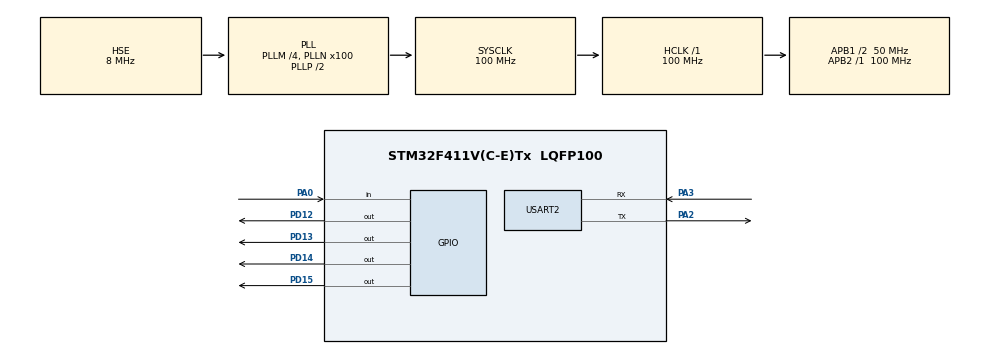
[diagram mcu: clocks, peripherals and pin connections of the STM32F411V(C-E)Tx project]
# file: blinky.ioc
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FREERTOS.Tasks01=defaultTask,24,128,StartDefaultTask,Default,NULL
Mcu.Family=STM32F4
Mcu.Name=STM32F411V(C-E)Tx
Mcu.Package=LQFP100
NVIC.PriorityGroup=NVIC_PRIORITYGROUP_4
NVIC.TIM1_UP_TIM10_IRQn=true\:0\:0\:false\:false\:true\:false\:false\:true
NVIC.TimeBase=TIM1_UP_TIM10_IRQn
NVIC.TimeBaseIP=TIM1
PA0-WKUP.Signal=GPIO_Input
PA13.Mode=Serial_Wire
PA13.Signal=SYS_JTMS-SWDIO
PA14.Mode=Serial_Wire
PA14.Signal=SYS_JTCK-SWCLK
PA2.Mode=Asynchronous
PA2.Signal=USART2_TX
PA3.Mode=Asynchronous
PA3.Signal=USART2_RX
PD12.Signal=GPIO_Output
PD13.Signal=GPIO_Output
PD14.Signal=GPIO_Output
PD15.Signal=GPIO_Output
PH0\ -\ OSC_IN.Mode=HSE-External-Oscillator
PH0\ -\ OSC_IN.Signal=RCC_OSC_IN
PH1\ -\ OSC_OUT.Mode=HSE-External-Oscillator
PH1\ -\ OSC_OUT.Signal=RCC_OSC_OUT
ProjectManager.HeapSize=0x200
ProjectManager.StackSize=0x400
ProjectManager.TargetToolchain=STM32CubeIDE
RCC.48MHZClocksFreq_Value=50000000
RCC.AHBFreq_Value=100000000
RCC.APB1CLKDivider=RCC_HCLK_DIV2
RCC.APB1Freq_Value=50000000
RCC.APB1TimFreq_Value=100000000
RCC.APB2Freq_Value=100000000
RCC.APB2TimFreq_Value=100000000
RCC.CortexFreq_Value=100000000
RCC.HCLKFreq_Value=100000000
RCC.HSE_VALUE=8000000
RCC.HSI_VALUE=16000000
RCC.PLLM=4
RCC.PLLN=100
RCC.PLLSourceVirtual=RCC_PLLSOURCE_HSE
RCC.SYSCLKFreq_VALUE=100000000
RCC.SYSCLKSource=RCC_SYSCLKSOURCE_PLLCLK
RCC.VCOOutputFreq_Value=200000000
USART2.VirtualMode=VM_ASYNC
VP_FREERTOS_VS_CMSIS_V2.Mode=CMSIS_V2
VP_SYS_VS_tim1.Mode=TIM1
board=custom

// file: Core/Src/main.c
/* USER CODE BEGIN Header */
/**
  ******************************************************************************
  * @file           : main.c
  * @brief          : Main program body
  ******************************************************************************
  * @attention
  *
  * <h2><center>&copy; Copyright (c) 2019 STMicroelectronics.
  * All rights reserved.</center></h2>
  *
  * This software component is licensed by ST under BSD 3-Clause license,
  * the "License"; You may not use this file except in compliance with the
  * License. You may obtain a copy of the License at:
  *                        opensource.org/licenses/BSD-3-Clause
  *

  https://www.keil.com/pack/doc/cmsis/RTOS2/html/group__CMSIS__RTOS__PoolMgmt.html#details

  Los grupos de memoria son bloques de memoria de tamaño fijo que son seguros para
  subprocesos. Funcionan mucho más rápido que el montón asignado dinámicamente y
  no sufren fragmentación. Al ser seguros para subprocesos, se puede acceder a
  ellos desde subprocesos e ISR por igual.

Un conjunto de memoria se puede ver como una lista vinculada de bloques de
memoria disponibles (no utilizados) de tamaño fijo e igual. La asignación de
memoria de un grupo (usando osMemoryPoolAlloc) simplemente desencadena un
bloque de la lista y le da el control al usuario. Liberar memoria al grupo
(usando osMemoryPoolFree) simplemente rechaza el bloque en la lista.
  ******************************************************************************
  */
/* USER CODE END Header */

#include "main.h"
#include "cmsis_os.h"

/* USER CODE BEGIN Includes */
#include "stdio.h"
/* USER CODE END Includes */

/* USER CODE BEGIN PD */
#define MEMPOOL_OBJECTS 16                      // number of Memory Pool Objects
/* USER CODE END PD */

UART_HandleTypeDef huart2;

typedef struct {                                // object data type
  uint8_t Buf[32];
  uint8_t Idx;
} MEM_BLOCK_t;

osMemoryPoolId_t mpid_MemPool;                  // memory pool id

osThreadId_t tid_Thread_MemPool;                // thread id

void SystemClock_Config(void);
static void MX_GPIO_Init(void);
static void MX_USART2_UART_Init(void);
void Thread_MemPool (void *argument);           // thread function

/* USER CODE BEGIN 0 */

int Init_MemPool (void) {

  mpid_MemPool = osMemoryPoolNew(MEMPOOL_OBJECTS, sizeof(MEM_BLOCK_t), NULL);
  if (mpid_MemPool == NULL) {
    ; // MemPool object not created, handle failure
  }

  tid_Thread_MemPool = osThreadNew(Thread_MemPool, NULL, NULL);
  if (tid_Thread_MemPool == NULL) {
    return(-1);
  }

  return(0);
}

/* USER CODE END 0 */

int main(void)
{

  /* MCU Configuration--------------------------------------------------------*/

  /* Reset of all peripherals, Initializes the Flash interface and the Systick. */
  HAL_Init();

  /* Configure the system clock */
  SystemClock_Config();

  /* Initialize all configured peripherals */
  MX_GPIO_Init();
  MX_USART2_UART_Init();

  osKernelInitialize();

  /* Create the thread(s) */
  /* definition and creation of defaultTask */
  Init_MemPool();
  /* USER CODE BEGIN RTOS_THREADS */

    char txData[50]= "";;
    sprintf(txData, "%s", "inicio\r\n");
    HAL_UART_Transmit(&huart2, (uint8_t *) txData, sizeof(txData),1000);
  /* add threads, ... */
  /* USER CODE END RTOS_THREADS */

  /* Start scheduler */
  osKernelStart();

  /* We should never get here as control is now taken by the scheduler */

  /* Infinite loop */
  while (1)
  {

  }
}

void SystemClock_Config(void)
{
  RCC_OscInitTypeDef RCC_OscInitStruct = {0};
  RCC_ClkInitTypeDef RCC_ClkInitStruct = {0};

  /** Configure the main internal regulator output voltage
  */
  __HAL_RCC_PWR_CLK_ENABLE();
  __HAL_PWR_VOLTAGESCALING_CONFIG(PWR_REGULATOR_VOLTAGE_SCALE1);
  /** Initializes the CPU, AHB and APB busses clocks
  */
  RCC_OscInitStruct.OscillatorType = RCC_OSCILLATORTYPE_HSE;
  RCC_OscInitStruct.HSEState = RCC_HSE_ON;
  RCC_OscInitStruct.PLL.PLLState = RCC_PLL_ON;
  RCC_OscInitStruct.PLL.PLLSource = RCC_PLLSOURCE_HSE;
  RCC_OscInitStruct.PLL.PLLM = 4;
  RCC_OscInitStruct.PLL.PLLN = 100;
  RCC_OscInitStruct.PLL.PLLP = RCC_PLLP_DIV2;
  RCC_OscInitStruct.PLL.PLLQ = 4;
  if (HAL_RCC_OscConfig(&RCC_OscInitStruct) != HAL_OK)
  {
    Error_Handler();
  }
  /** Initializes the CPU, AHB and APB busses clocks
  */
  RCC_ClkInitStruct.ClockType = RCC_CLOCKTYPE_HCLK|RCC_CLOCKTYPE_SYSCLK
                              |RCC_CLOCKTYPE_PCLK1|RCC_CLOCKTYPE_PCLK2;
  RCC_ClkInitStruct.SYSCLKSource = RCC_SYSCLKSOURCE_PLLCLK;
  RCC_ClkInitStruct.AHBCLKDivider = RCC_SYSCLK_DIV1;
  RCC_ClkInitStruct.APB1CLKDivider = RCC_HCLK_DIV2;
  RCC_ClkInitStruct.APB2CLKDivider = RCC_HCLK_DIV1;

  if (HAL_RCC_ClockConfig(&RCC_ClkInitStruct, FLASH_LATENCY_3) != HAL_OK)
  {
    Error_Handler();
  }
}

static void MX_USART2_UART_Init(void)
{

  huart2.Instance = USART2;
  huart2.Init.BaudRate = 115200;
  huart2.Init.WordLength = UART_WORDLENGTH_8B;
  huart2.Init.StopBits = UART_STOPBITS_1;
  huart2.Init.Parity = UART_PARITY_NONE;
  huart2.Init.Mode = UART_MODE_TX_RX;
  huart2.Init.HwFlowCtl = UART_HWCONTROL_NONE;
  huart2.Init.OverSampling = UART_OVERSAMPLING_16;
  if (HAL_UART_Init(&huart2) != HAL_OK)
  {
    Error_Handler();
  }

}

static void MX_GPIO_Init(void)
{
  GPIO_InitTypeDef GPIO_InitStruct = {0};

  /* GPIO Ports Clock Enable */
  __HAL_RCC_GPIOH_CLK_ENABLE();
  __HAL_RCC_GPIOA_CLK_ENABLE();
  __HAL_RCC_GPIOD_CLK_ENABLE();

  /*Configure GPIO pin Output Level */
  HAL_GPIO_WritePin(GPIOD, GPIO_PIN_12|GPIO_PIN_13|GPIO_PIN_14|GPIO_PIN_15, GPIO_PIN_RESET);

  /*Configure GPIO pin : PA0 */
  GPIO_InitStruct.Pin = GPIO_PIN_0;
  GPIO_InitStruct.Mode = GPIO_MODE_INPUT;
  GPIO_InitStruct.Pull = GPIO_NOPULL;
  HAL_GPIO_Init(GPIOA, &GPIO_InitStruct);

  /*Configure GPIO pins : PD12 PD13 PD14 PD15 */
  GPIO_InitStruct.Pin = GPIO_PIN_12|GPIO_PIN_13|GPIO_PIN_14|GPIO_PIN_15;
  GPIO_InitStruct.Mode = GPIO_MODE_OUTPUT_PP;
  GPIO_InitStruct.Pull = GPIO_NOPULL;
  GPIO_InitStruct.Speed = GPIO_SPEED_FREQ_LOW;
  HAL_GPIO_Init(GPIOD, &GPIO_InitStruct);

}

void Thread_MemPool (void *argument) {
  MEM_BLOCK_t *pMem;
  osStatus_t status;

  while (1) {
    ; // Insert thread code here...

    pMem = (MEM_BLOCK_t *)osMemoryPoolAlloc(mpid_MemPool, 0U);  // get Mem Block
    if (pMem != NULL) {                                         // Mem Block was available
      pMem->Buf[0] = 0x55U;                                     // do some work...
      pMem->Idx    = 0U;

      status = osMemoryPoolFree(mpid_MemPool, pMem);            // free mem block
      switch (status)  {
        case osOK:
          break;
        case osErrorParameter:
          break;
        case osErrorNoMemory:
          break;
        default:
          break;
      }
    }

    osThreadYield();                                            // suspend thread
  }
}

void HAL_TIM_PeriodElapsedCallback(TIM_HandleTypeDef *htim)
{
  if (htim->Instance == TIM1) {
    HAL_IncTick();
  }
}

void Error_Handler(void)
{
}

/************************ (C) COPYRIGHT STMicroelectronics *****END OF FILE****/
